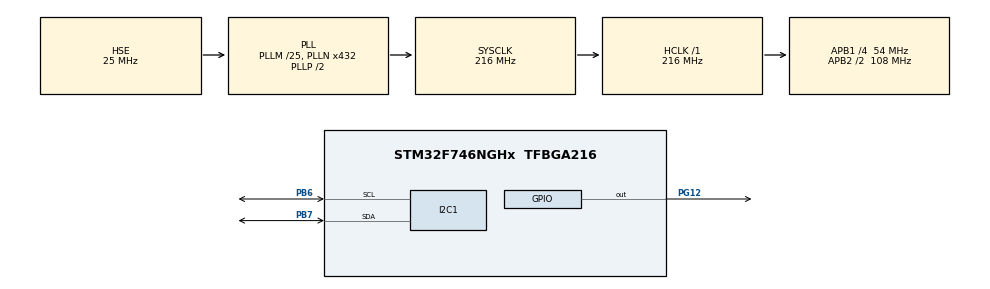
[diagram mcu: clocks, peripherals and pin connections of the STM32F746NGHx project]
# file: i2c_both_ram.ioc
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I2C1.Timing=0x20404768
Mcu.Family=STM32F7
Mcu.Name=STM32F746NGHx
Mcu.Package=TFBGA216
NVIC.PriorityGroup=NVIC_PRIORITYGROUP_4
PB6.GPIO_Pu=GPIO_PULLUP
PB6.Mode=I2C
PB6.Signal=I2C1_SCL
PB7.GPIO_Pu=GPIO_PULLUP
PB7.Mode=I2C
PB7.Signal=I2C1_SDA
PG12.Signal=GPIO_Output
PH0/OSC_IN.Mode=HSE-External-Oscillator
PH0/OSC_IN.Signal=RCC_OSC_IN
PH1/OSC_OUT.Mode=HSE-External-Oscillator
PH1/OSC_OUT.Signal=RCC_OSC_OUT
ProjectManager.HeapSize=0x200
ProjectManager.StackSize=0x400
ProjectManager.TargetToolchain=STM32CubeIDE
RCC.AHBFreq_Value=216000000
RCC.APB1CLKDivider=RCC_HCLK_DIV4
RCC.APB1Freq_Value=54000000
RCC.APB1TimFreq_Value=108000000
RCC.APB2CLKDivider=RCC_HCLK_DIV2
RCC.APB2Freq_Value=108000000
RCC.APB2TimFreq_Value=216000000
RCC.CortexFreq_Value=216000000
RCC.HCLKFreq_Value=216000000
RCC.HSE_VALUE=25000000
RCC.HSI_VALUE=16000000
RCC.LSE_VALUE=32768
RCC.PLLM=25
RCC.PLLN=432
RCC.PLLSourceVirtual=RCC_PLLSOURCE_HSE
RCC.SYSCLKFreq_VALUE=216000000
RCC.SYSCLKSource=RCC_SYSCLKSOURCE_PLLCLK
RCC.USBFreq_Value=216000000
RCC.VCOOutputFreq_Value=432000000
board=STM32F746G-DISCO

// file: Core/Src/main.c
///* USER CODE BEGIN Header */
///**
//  ******************************************************************************
//  * @file           : main.c
//  * @brief          : Main program body
//  ******************************************************************************
//  * @attention
//  *
//  * Copyright (c) 2025 STMicroelectronics.
//  * All rights reserved.
//  *
//  * This software is licensed under terms that can be found in the LICENSE file
//  * in the root directory of this software component.
//  * If no LICENSE file comes with this software, it is provided AS-IS.
//  *
//  ******************************************************************************
//  */
///* USER CODE END Header */
///* Includes ------------------------------------------------------------------*/
//#include "main.h"
//
///* Private includes ----------------------------------------------------------*/
///* USER CODE BEGIN Includes */
//#define EEPROM_I2C_FACTORY			(0x50 << 1)
//#define EEPROM_I2C_APPLICATION		(0x54 << 1)
//#define EEPROM_TIMEOUT				100
//#define EEPROM_MEM_ADDR				0x00
//uint8_t writeData[]= "Factory Ram";
//uint8_t readData[sizeof(writeData)] = {0};
//uint8_t readData_application_ram[sizeof(writeData)] = {0};
///* USER CODE END Includes */
//
///* Private typedef -----------------------------------------------------------*/
///* USER CODE BEGIN PTD */
//
///* USER CODE END PTD */
//
///* Private define ------------------------------------------------------------*/
///* USER CODE BEGIN PD */
//
///* USER CODE END PD */
//
///* Private macro -------------------------------------------------------------*/
///* USER CODE BEGIN PM */
//
///* USER CODE END PM */
//
///* Private variables ---------------------------------------------------------*/
//
//I2C_HandleTypeDef hi2c1;
//
///* USER CODE BEGIN PV */
//
///* USER CODE END PV */
//
///* Private function prototypes -----------------------------------------------*/
//void SystemClock_Config(void);
//static void MX_GPIO_Init(void);
//static void MX_I2C1_Init(void);
///* USER CODE BEGIN PFP */
//
///* USER CODE END PFP */
//
///* Private user code ---------------------------------------------------------*/
///* USER CODE BEGIN 0 */
//
///* USER CODE END 0 */
//
///**
//  * @brief  The application entry point.
//  * @retval int
//  */
//int main(void)
//{
//
//  /* USER CODE BEGIN 1 */
//
//  /* USER CODE END 1 */
//
//  /* MCU Configuration--------------------------------------------------------*/
//
//  /* Reset of all peripherals, Initializes the Flash interface and the Systick. */
//  HAL_Init();
//
//  /* USER CODE BEGIN Init */
//
//  /* USER CODE END Init */
//
//  /* Configure the system clock */
//  SystemClock_Config();
//
//  /* USER CODE BEGIN SysInit */
//
//  /* USER CODE END SysInit */
//
//  /* Initialize all configured peripherals */
//  MX_GPIO_Init();
//  MX_I2C1_Init();
//  /* USER CODE BEGIN 2 */
//  HAL_GPIO_WritePin(GPIOG, GPIO_PIN_12, GPIO_PIN_SET);
//  volatile HAL_StatusTypeDef writeStatus = HAL_I2C_Mem_Write(
//       &hi2c1,
//       EEPROM_I2C_FACTORY,
//       EEPROM_MEM_ADDR,
//       I2C_MEMADD_SIZE_8BIT,
//       writeData,
//       sizeof(writeData),
//       EEPROM_TIMEOUT
//   );
//
//   HAL_Delay(5);  // EEPROM write cycle time
//
//   /* EEPROM Read */
//   volatile HAL_StatusTypeDef readStatus = HAL_I2C_Mem_Read(
//       &hi2c1,
//       EEPROM_I2C_FACTORY,
//       EEPROM_MEM_ADDR,
//       I2C_MEMADD_SIZE_8BIT,
//       readData,
//       sizeof(readData),
//       EEPROM_TIMEOUT
//   );
//   HAL_GPIO_WritePin(GPIOG, GPIO_PIN_12, GPIO_PIN_RESET);
//   volatile HAL_StatusTypeDef writeStatus_application_ram = HAL_I2C_Mem_Write(
//          &hi2c1,
//          EEPROM_I2C_APPLICATION,
//          EEPROM_MEM_ADDR,
//          I2C_MEMADD_SIZE_8BIT,
//          readData,
//          sizeof(readData),
//          EEPROM_TIMEOUT
//      );
//
//      HAL_Delay(5);  // EEPROM write cycle time
//     volatile HAL_StatusTypeDef readStatus_application_ram = HAL_I2C_Mem_Read(
//             &hi2c1,
//             EEPROM_I2C_APPLICATION,
//             EEPROM_MEM_ADDR,
//             I2C_MEMADD_SIZE_8BIT,
//             readData_application_ram,
//             sizeof(readData_application_ram),
//             EEPROM_TIMEOUT
//         );
//
//   if (writeStatus == HAL_OK && readStatus == HAL_OK)
//      {
//          if (memcmp(writeData, readData, sizeof(writeData)) == 0)
//          {
//              // Data verified successfully
//          }
//          else
//          {
//              // Data mismatch
//          }
//      }
//   if (writeStatus_application_ram == HAL_OK && readStatus_application_ram == HAL_OK)
//         {
//             if (memcmp(readData, readData_application_ram, sizeof(writeData)) == 0)
//             {
//                 // Data verified successfully
//             }
//             else
//             {
//                 // Data mismatch
//             }
//         }
//  /* USER CODE END 2 */
//
//  /* Infinite loop */
//  /* USER CODE BEGIN WHILE */
//  while (1)
//  {
//    /* USER CODE END WHILE */
//
//    /* USER CODE BEGIN 3 */
//  }
//  /* USER CODE END 3 */
//}
//
///**
//  * @brief System Clock Configuration
//  * @retval None
//  */
//void SystemClock_Config(void)
//{
//  RCC_OscInitTypeDef RCC_OscInitStruct = {0};
//  RCC_ClkInitTypeDef RCC_ClkInitStruct = {0};
//
//  /** Configure the main internal regulator output voltage
//  */
//  __HAL_RCC_PWR_CLK_ENABLE();
//  __HAL_PWR_VOLTAGESCALING_CONFIG(PWR_REGULATOR_VOLTAGE_SCALE1);
//
//  /** Initializes the RCC Oscillators according to the specified parameters
//  * in the RCC_OscInitTypeDef structure.
//  */
//  RCC_OscInitStruct.OscillatorType = RCC_OSCILLATORTYPE_HSE;
//  RCC_OscInitStruct.HSEState = RCC_HSE_ON;
//  RCC_OscInitStruct.PLL.PLLState = RCC_PLL_ON;
//  RCC_OscInitStruct.PLL.PLLSource = RCC_PLLSOURCE_HSE;
//  RCC_OscInitStruct.PLL.PLLM = 25;
//  RCC_OscInitStruct.PLL.PLLN = 432;
//  RCC_OscInitStruct.PLL.PLLP = RCC_PLLP_DIV2;
//  RCC_OscInitStruct.PLL.PLLQ = 2;
//  if (HAL_RCC_OscConfig(&RCC_OscInitStruct) != HAL_OK)
//  {
//    Error_Handler();
//  }
//
//  /** Activate the Over-Drive mode
//  */
//  if (HAL_PWREx_EnableOverDrive() != HAL_OK)
//  {
//    Error_Handler();
//  }
//
//  /** Initializes the CPU, AHB and APB buses clocks
//  */
//  RCC_ClkInitStruct.ClockType = RCC_CLOCKTYPE_HCLK|RCC_CLOCKTYPE_SYSCLK
//                              |RCC_CLOCKTYPE_PCLK1|RCC_CLOCKTYPE_PCLK2;
//  RCC_ClkInitStruct.SYSCLKSource = RCC_SYSCLKSOURCE_PLLCLK;
//  RCC_ClkInitStruct.AHBCLKDivider = RCC_SYSCLK_DIV1;
//  RCC_ClkInitStruct.APB1CLKDivider = RCC_HCLK_DIV4;
//  RCC_ClkInitStruct.APB2CLKDivider = RCC_HCLK_DIV2;
//
//  if (HAL_RCC_ClockConfig(&RCC_ClkInitStruct, FLASH_LATENCY_7) != HAL_OK)
//  {
//    Error_Handler();
//  }
//}
//
///**
//  * @brief I2C1 Initialization Function
//  * @param None
//  * @retval None
//  */
//static void MX_I2C1_Init(void)
//{
//
//  /* USER CODE BEGIN I2C1_Init 0 */
//
//  /* USER CODE END I2C1_Init 0 */
//
//  /* USER CODE BEGIN I2C1_Init 1 */
//
//  /* USER CODE END I2C1_Init 1 */
//  hi2c1.Instance = I2C1;
//  hi2c1.Init.Timing = 0x20404768;
//  hi2c1.Init.OwnAddress1 = 0;
//  hi2c1.Init.AddressingMode = I2C_ADDRESSINGMODE_7BIT;
//  hi2c1.Init.DualAddressMode = I2C_DUALADDRESS_DISABLE;
//  hi2c1.Init.OwnAddress2 = 0;
//  hi2c1.Init.OwnAddress2Masks = I2C_OA2_NOMASK;
//  hi2c1.Init.GeneralCallMode = I2C_GENERALCALL_DISABLE;
//  hi2c1.Init.NoStretchMode = I2C_NOSTRETCH_DISABLE;
//  if (HAL_I2C_Init(&hi2c1) != HAL_OK)
//  {
//    Error_Handler();
//  }
//
//  /** Configure Analogue filter
//  */
//  if (HAL_I2CEx_ConfigAnalogFilter(&hi2c1, I2C_ANALOGFILTER_ENABLE) != HAL_OK)
//  {
//    Error_Handler();
//  }
//
//  /** Configure Digital filter
//  */
//  if (HAL_I2CEx_ConfigDigitalFilter(&hi2c1, 0) != HAL_OK)
//  {
//    Error_Handler();
//  }
//  /* USER CODE BEGIN I2C1_Init 2 */
//
//  /* USER CODE END I2C1_Init 2 */
//
//}
//
///**
//  * @brief GPIO Initialization Function
//  * @param None
//  * @retval None
//  */
//static void MX_GPIO_Init(void)
//{
//  GPIO_InitTypeDef GPIO_InitStruct = {0};
//  /* USER CODE BEGIN MX_GPIO_Init_1 */
//
//  /* USER CODE END MX_GPIO_Init_1 */
//
//  /* GPIO Ports Clock Enable */
//  __HAL_RCC_GPIOB_CLK_ENABLE();
//  __HAL_RCC_GPIOG_CLK_ENABLE();
//  __HAL_RCC_GPIOH_CLK_ENABLE();
//
//  /*Configure GPIO pin Output Level */
//  HAL_GPIO_WritePin(GPIOG, GPIO_PIN_12, GPIO_PIN_RESET);
//
//  /*Configure GPIO pin : PG12 */
//  GPIO_InitStruct.Pin = GPIO_PIN_12;
//  GPIO_InitStruct.Mode = GPIO_MODE_OUTPUT_PP;
//  GPIO_InitStruct.Pull = GPIO_NOPULL;
//  GPIO_InitStruct.Speed = GPIO_SPEED_FREQ_LOW;
//  HAL_GPIO_Init(GPIOG, &GPIO_InitStruct);
//
//  /* USER CODE BEGIN MX_GPIO_Init_2 */
//
//  /* USER CODE END MX_GPIO_Init_2 */
//}
//
///* USER CODE BEGIN 4 */
//
///* USER CODE END 4 */
//
///**
//  * @brief  This function is executed in case of error occurrence.
//  * @retval None
//  */
//void Error_Handler(void)
//{
//  /* USER CODE BEGIN Error_Handler_Debug */
//  /* User can add his own implementation to report the HAL error return state */
//  __disable_irq();
//  while (1)
//  {
//  }
//  /* USER CODE END Error_Handler_Debug */
//}
//
//#ifdef  USE_FULL_ASSERT
///**
//  * @brief  Reports the name of the source file and the source line number
//  *         where the assert_param error has occurred.
//  * @param  file: pointer to the source file name
//  * @param  line: assert_param error line source number
//  * @retval None
//  */
//void assert_failed(uint8_t *file, uint32_t line)
//{
//  /* USER CODE BEGIN 6 */
//  /* User can add his own implementation to report the file name and line number,
//     ex: printf("Wrong parameters value: file %s on line %d\r\n", file, line) */
//  /* USER CODE END 6 */
//}
//#endif /* USE_FULL_ASSERT */

/* USER CODE BEGIN Header */
/**
  ******************************************************************************
  * @file           : main.c
  * @brief          : Main program body
  ******************************************************************************
  * @attention
  *
  * Copyright (c) 2025 STMicroelectronics.
  * All rights reserved.
  *
  * This software is licensed under terms that can be found in the LICENSE file
  * in the root directory of this software component.
  * If no LICENSE file comes with this software, it is provided AS-IS.
  *
  ******************************************************************************
  */
/* USER CODE END Header */
#include "main.h"

/* USER CODE BEGIN Includes */
#define EEPROM_I2C_FACTORY			(0x50 << 1)
#define EEPROM_I2C_APPLICATION		(0x54 << 1)
#define EEPROM_TIMEOUT				100
#define EEPROM_MEM_ADDR				0x00
uint8_t writeData[]= "Factory Ram";
uint8_t readData[sizeof(writeData)] = {0};
uint8_t readData_application_ram[sizeof(writeData)] = {0};
/* USER CODE END Includes */

I2C_HandleTypeDef hi2c1;

void SystemClock_Config(void);
static void MX_GPIO_Init(void);
static void MX_I2C1_Init(void);

int main(void)
{

  /* MCU Configuration--------------------------------------------------------*/

  /* Reset of all peripherals, Initializes the Flash interface and the Systick. */
  HAL_Init();

  /* Configure the system clock */
  SystemClock_Config();

  /* Initialize all configured peripherals */
  MX_GPIO_Init();
  MX_I2C1_Init();
  /* USER CODE BEGIN 2 */
  HAL_GPIO_WritePin(GPIOG, GPIO_PIN_12, GPIO_PIN_SET);
  volatile HAL_StatusTypeDef writeStatus = HAL_I2C_Mem_Write(
       &hi2c1,
       EEPROM_I2C_FACTORY,
       EEPROM_MEM_ADDR,
       I2C_MEMADD_SIZE_8BIT,
       writeData,
       sizeof(writeData),
       EEPROM_TIMEOUT
   );

   HAL_Delay(5);  // EEPROM write cycle time

   /* EEPROM Read */
   volatile HAL_StatusTypeDef readStatus = HAL_I2C_Mem_Read(
       &hi2c1,
       EEPROM_I2C_FACTORY,
       EEPROM_MEM_ADDR,
       I2C_MEMADD_SIZE_8BIT,
       readData,
       sizeof(readData),
       EEPROM_TIMEOUT
   );
   HAL_GPIO_WritePin(GPIOG, GPIO_PIN_12, GPIO_PIN_RESET);
   volatile HAL_StatusTypeDef writeStatus_application_ram = HAL_I2C_Mem_Write(
          &hi2c1,
          EEPROM_I2C_APPLICATION,
          EEPROM_MEM_ADDR,
          I2C_MEMADD_SIZE_8BIT,
          readData,
          sizeof(readData),
          EEPROM_TIMEOUT
      );

      HAL_Delay(5);  // EEPROM write cycle time
     volatile HAL_StatusTypeDef readStatus_application_ram = HAL_I2C_Mem_Read(
             &hi2c1,
             EEPROM_I2C_APPLICATION,
             EEPROM_MEM_ADDR,
             I2C_MEMADD_SIZE_8BIT,
             readData_application_ram,
             sizeof(readData_application_ram),
             EEPROM_TIMEOUT
         );

   if (writeStatus == HAL_OK && readStatus == HAL_OK)
      {
          if (memcmp(writeData, readData, sizeof(writeData)) == 0)
          {
              // Data verified successfully
          }
          else
          {
              // Data mismatch
          }
      }
   if (writeStatus_application_ram == HAL_OK && readStatus_application_ram == HAL_OK)
         {
             if (memcmp(readData, readData_application_ram, sizeof(writeData)) == 0)
             {
                 // Data verified successfully
             }
             else
             {
                 // Data mismatch
             }
         }
  /* USER CODE END 2 */

  /* Infinite loop */
  while (1)
  {

  }
}

void SystemClock_Config(void)
{
  RCC_OscInitTypeDef RCC_OscInitStruct = {0};
  RCC_ClkInitTypeDef RCC_ClkInitStruct = {0};

  /** Configure the main internal regulator output voltage
  */
  __HAL_RCC_PWR_CLK_ENABLE();
  __HAL_PWR_VOLTAGESCALING_CONFIG(PWR_REGULATOR_VOLTAGE_SCALE1);

  /** Initializes the RCC Oscillators according to the specified parameters
  * in the RCC_OscInitTypeDef structure.
  */
  RCC_OscInitStruct.OscillatorType = RCC_OSCILLATORTYPE_HSE;
  RCC_OscInitStruct.HSEState = RCC_HSE_ON;
  RCC_OscInitStruct.PLL.PLLState = RCC_PLL_ON;
  RCC_OscInitStruct.PLL.PLLSource = RCC_PLLSOURCE_HSE;
  RCC_OscInitStruct.PLL.PLLM = 25;
  RCC_OscInitStruct.PLL.PLLN = 432;
  RCC_OscInitStruct.PLL.PLLP = RCC_PLLP_DIV2;
  RCC_OscInitStruct.PLL.PLLQ = 2;
  if (HAL_RCC_OscConfig(&RCC_OscInitStruct) != HAL_OK)
  {
    Error_Handler();
  }

  /** Activate the Over-Drive mode
  */
  if (HAL_PWREx_EnableOverDrive() != HAL_OK)
  {
    Error_Handler();
  }

  /** Initializes the CPU, AHB and APB buses clocks
  */
  RCC_ClkInitStruct.ClockType = RCC_CLOCKTYPE_HCLK|RCC_CLOCKTYPE_SYSCLK
                              |RCC_CLOCKTYPE_PCLK1|RCC_CLOCKTYPE_PCLK2;
  RCC_ClkInitStruct.SYSCLKSource = RCC_SYSCLKSOURCE_PLLCLK;
  RCC_ClkInitStruct.AHBCLKDivider = RCC_SYSCLK_DIV1;
  RCC_ClkInitStruct.APB1CLKDivider = RCC_HCLK_DIV4;
  RCC_ClkInitStruct.APB2CLKDivider = RCC_HCLK_DIV2;

  if (HAL_RCC_ClockConfig(&RCC_ClkInitStruct, FLASH_LATENCY_7) != HAL_OK)
  {
    Error_Handler();
  }
}

static void MX_I2C1_Init(void)
{

  hi2c1.Instance = I2C1;
  hi2c1.Init.Timing = 0x20404768;
  hi2c1.Init.OwnAddress1 = 0;
  hi2c1.Init.AddressingMode = I2C_ADDRESSINGMODE_7BIT;
  hi2c1.Init.DualAddressMode = I2C_DUALADDRESS_DISABLE;
  hi2c1.Init.OwnAddress2 = 0;
  hi2c1.Init.OwnAddress2Masks = I2C_OA2_NOMASK;
  hi2c1.Init.GeneralCallMode = I2C_GENERALCALL_DISABLE;
  hi2c1.Init.NoStretchMode = I2C_NOSTRETCH_DISABLE;
  if (HAL_I2C_Init(&hi2c1) != HAL_OK)
  {
    Error_Handler();
  }

  /** Configure Analogue filter
  */
  if (HAL_I2CEx_ConfigAnalogFilter(&hi2c1, I2C_ANALOGFILTER_ENABLE) != HAL_OK)
  {
    Error_Handler();
  }

  /** Configure Digital filter
  */
  if (HAL_I2CEx_ConfigDigitalFilter(&hi2c1, 0) != HAL_OK)
  {
    Error_Handler();
  }

}

static void MX_GPIO_Init(void)
{
  GPIO_InitTypeDef GPIO_InitStruct = {0};

  /* GPIO Ports Clock Enable */
  __HAL_RCC_GPIOB_CLK_ENABLE();
  __HAL_RCC_GPIOG_CLK_ENABLE();
  __HAL_RCC_GPIOH_CLK_ENABLE();

  /*Configure GPIO pin Output Level */
  HAL_GPIO_WritePin(GPIOG, GPIO_PIN_12, GPIO_PIN_RESET);

  /*Configure GPIO pin : PG12 */
  GPIO_InitStruct.Pin = GPIO_PIN_12;
  GPIO_InitStruct.Mode = GPIO_MODE_OUTPUT_PP;
  GPIO_InitStruct.Pull = GPIO_NOPULL;
  GPIO_InitStruct.Speed = GPIO_SPEED_FREQ_LOW;
  HAL_GPIO_Init(GPIOG, &GPIO_InitStruct);

}

void Error_Handler(void)
{
  __disable_irq();
  while (1)
  {
  }
}
